# ATSAML11E16A register map
Vendor: Microchip Technology; Series: SAML11; File version: 0
CPU: CM23 r0p0, selectable endian, MPU, no FPU, 2 interrupt priority bits
Registers are 32-bit, read-write, reset 0x0 unless marked. A register's access mark holds for its fields unless they carry their own. Offsets are from the block's base; [hi:lo] are bit positions; {n}, {i} and the like mark numbered series; 'fields as' and 'values as' point back to an identical list.

## TRNG — True Random Generator
Base 0x42002800; register names take the prefix TRNG_
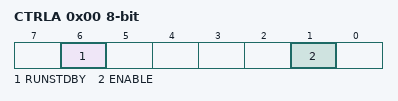
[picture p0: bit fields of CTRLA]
0x00 CTRLA 8-bit — Control A
  [6] RUNSTDBY — Run in Standby
  [1] ENABLE
0x04 EVCTRL 8-bit — Event Control
  [0] DATARDYEO — Data Ready Event Output
0x08 INTENCLR 8-bit — Interrupt Enable Clear
  [0] DATARDY — Data Ready Interrupt Enable
0x09 INTENSET 8-bit — Interrupt Enable Set
  [0] DATARDY — Data Ready Interrupt Enable
0x0A INTFLAG 8-bit — Interrupt Flag Status and Clear
  [0] DATARDY — Data Ready Interrupt Flag
0x20 DATA ro — Output Data

## WDT — Watchdog Timer
Base 0x40002000; register names take the prefix WDT_
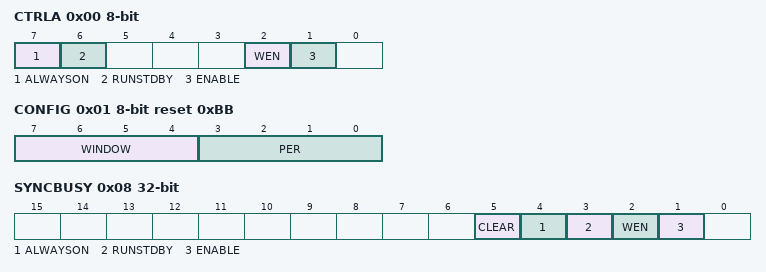
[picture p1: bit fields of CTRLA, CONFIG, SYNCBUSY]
0x00 CTRLA 8-bit — Control
  [7] ALWAYSON
  [6] RUNSTDBY — Run During Standby
  [2] WEN — Watchdog Timer Window Mode Enable
  [1] ENABLE
0x01 CONFIG 8-bit reset 0xBB — Configuration
  [7:4] WINDOW — Window Mode Time-Out Period
    0=CYC8 (8 clock cycles); 1=CYC16 (16 clock cycles); 2=CYC32 (32 clock cycles); 3=CYC64 (64 clock cycles); 4=CYC128 (128 clock cycles); 5=CYC256 (256 clock cycles); 6=CYC512 (512 clock cycles); 7=CYC1024 (1024 clock cycles); 8=CYC2048 (2048 clock cycles); 9=CYC4096 (4096 clock cycles); 10=CYC8192 (8192 clock cycles); 11=CYC16384 (16384 clock cycles)
  [3:0] PER — Time-Out Period
    values as WINDOW
0x02 EWCTRL 8-bit reset 0xB — Early Warning Interrupt Control
  [3:0] EWOFFSET — Early Warning Interrupt Time Offset
    values as CONFIG.WINDOW
0x04 INTENCLR 8-bit — Interrupt Enable Clear
  [0] EW — Early Warning Interrupt Enable
0x05 INTENSET 8-bit — Interrupt Enable Set
  [0] EW — Early Warning Interrupt Enable
0x06 INTFLAG 8-bit — Interrupt Flag Status and Clear
  [0] EW — Early Warning
0x08 SYNCBUSY ro — Synchronization Busy
  [5] CLEAR — Clear Synchronization Busy
  [4] ALWAYSON — Always-On Synchronization Busy
  [3] RUNSTDBY — Run During Standby Synchronization Busy
  [2] WEN — Window Enable Synchronization Busy
  [1] ENABLE — Enable Synchronization Busy
0x0C CLEAR 8-bit wo
  [7:0] CLEAR — Watchdog Clear
    165=KEY (Clear Key)

## MPU — Memory Protection Unit
Base 0xE000ED90; register names take the prefix MPU_
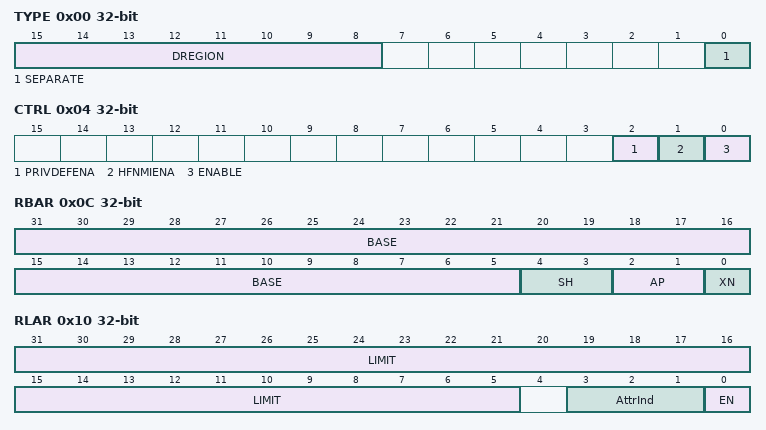
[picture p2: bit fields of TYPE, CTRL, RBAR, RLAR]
0x00 TYPE ro — MPU Type Register
  [15:8] DREGION — Number of Data Regions
  [0] SEPARATE — Instructions and Data Region (always 0)
0x04 CTRL — MPU Control Register
  [2] PRIVDEFENA — Privileged default enable
  [1] HFNMIENA — Hard Fault and NMI enable
  [0] ENABLE — MPU Enable
0x08 RNR — MPU Region Number Register
  [7:0] REGION — Region referenced by RBAR and RLAR
0x0C RBAR — MPU Region Base Address Register
  [31:5] BASE — Region base address
  [4:3] SH — Shareability domain of MPU region for Normal memory
    0=NON (Non-shareable); 2=OUTER (Outer Shareable); 3=INNER (Inner Shareable)
  [2:1] AP — Access Permissions for this MPU region
    0=Read/write by privileged code only; 1=Read/write by any privilege level; 2=Read-only by privileged code only; 3=Read-only by any privilege level
  [0] XN — Execute Never for this MPU region
    0=Execution only permitted if read permitted; 1=Execution not permitted
0x10 RLAR — MPU Region Limit Address Register
  [31:5] LIMIT — Upper inclusive limit of the selected MPU memory region
  [3:1] AttrInd — Attribute index
  [0] EN — MPU region enable
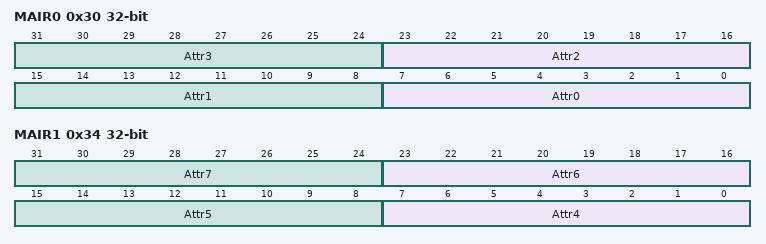
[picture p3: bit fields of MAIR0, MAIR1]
0x30 MAIR0 — MPU Memory Attribute Indirection Register 0
  [8n+7:8n] Attr{n} (n=0..3) — Memory attribute encoding for MPU regions with AttrIndx {n}
0x34 MAIR1 — MPU Memory Attribute Indirection Register 1
  [8n-25:8n-32] Attr{n} (n=4..7) — Memory attribute encoding for MPU regions with AttrIndx {n}

## NVIC — Nested Vectored Interrupt Controller
Base 0xE000E100; register names take the prefix NVIC_
{0x0+4i} ISER[{i}] (i=0..1) — Interrupt Set Enable Register
  [31:0] SETENA — Interrupt set enable bits
{0x80+4i} ICER[{i}] (i=0..1) — Interrupt Clear Enable Register
  [31:0] CLRENA — Interrupt clear-enable bits
{0x100+4i} ISPR[{i}] (i=0..1) — Interrupt Set Pending Register
  [31:0] SETPEND — Interrupt set-pending bits
{0x180+4i} ICPR[{i}] (i=0..1) — Interrupt Clear Pending Register
  [31:0] CLRPEND — Interrupt clear-pending bits
{0x200+4i} IABR[{i}] (i=0..1) — Interrupt Active Register
{0x280+4i} ITNS[{i}] (i=0..1) — Interrupt Target Non-Secure Register
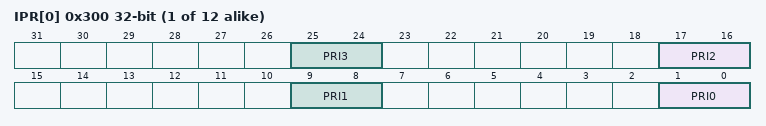
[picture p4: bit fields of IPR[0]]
{0x300+4i} IPR[{i}] (i=0..11) — Interrupt Priority Register n
  [8n+1:8n] PRI{n} (n=0..3) — Priority of interrupt n
